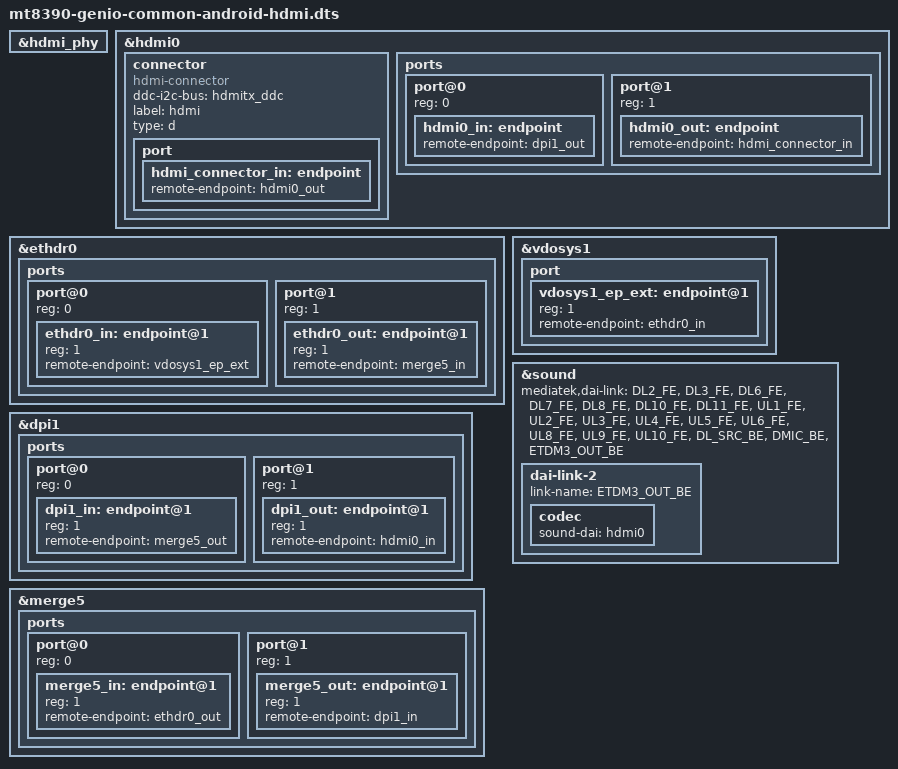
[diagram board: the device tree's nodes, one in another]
// SPDX-License-Identifier: GPL-2.0
/*
 * Copyright (c) 2025 BayLibre, SAS.
 * Author: Vitor Sato Eschholz <vsatoes@baylibre.com>
 */

/dts-v1/;
/plugin/;

#include <dt-bindings/gpio/gpio.h>
#include <dt-bindings/pinctrl/mediatek,mt8188-pinfunc.h>

#include "mt8390-genio-common-android.dtsi"

&hdmi_phy {
	status = "okay";
};

&hdmi0 {
	status = "okay";

	connector {
		compatible = "hdmi-connector";
		ddc-i2c-bus = <&hdmitx_ddc>;
		label = "hdmi";
		type = "d";

		port {
			hdmi_connector_in: endpoint {
				remote-endpoint = <&hdmi0_out>;
			};
		};
	};

	ports {
		#address-cells = <1>;
		#size-cells = <0>;

		port@0 {
			reg = <0>;

			hdmi0_in: endpoint {
				remote-endpoint = <&dpi1_out>;
			};
		};

		port@1 {
			reg = <1>;

			hdmi0_out: endpoint {
				remote-endpoint = <&hdmi_connector_in>;
			};
		};
	};
};

&ethdr0 {
	ports {
		#address-cells = <1>;
		#size-cells = <0>;

		port@0 {
			#address-cells = <1>;
			#size-cells = <0>;
			reg = <0>;

			ethdr0_in: endpoint@1 {
				reg = <1>;
				remote-endpoint = <&vdosys1_ep_ext>;
			};
		};

		port@1 {
			#address-cells = <1>;
			#size-cells = <0>;
			reg = <1>;

			ethdr0_out: endpoint@1 {
				reg = <1>;
				remote-endpoint = <&merge5_in>;
			};
		};
	};
};

&dpi1 {
	status = "okay";

	ports {
		#address-cells = <1>;
		#size-cells = <0>;

		port@0 {
			#address-cells = <1>;
			#size-cells = <0>;
			reg = <0>;

			dpi1_in: endpoint@1 {
				reg = <1>;
				remote-endpoint = <&merge5_out>;
			};
		};

		port@1 {
			#address-cells = <1>;
			#size-cells = <0>;
			reg = <1>;

			dpi1_out: endpoint@1 {
				reg = <1>;
				remote-endpoint = <&hdmi0_in>;
			};
		};
	};
};

&merge5 {
	ports {
		#address-cells = <1>;
		#size-cells = <0>;

		port@0 {
			#address-cells = <1>;
			#size-cells = <0>;
			reg = <0>;

			merge5_in: endpoint@1 {
				reg = <1>;
				remote-endpoint = <&ethdr0_out>;
			};
		};

		port@1 {
			#address-cells = <1>;
			#size-cells = <0>;
			reg = <1>;

			merge5_out: endpoint@1 {
				reg = <1>;
				remote-endpoint = <&dpi1_in>;
			};
		};
	};
};

&vdosys1 {
	port {
		#address-cells = <1>;
		#size-cells = <0>;

		vdosys1_ep_ext: endpoint@1 {
			reg = <1>;
			remote-endpoint = <&ethdr0_in>;
		};
	};
};

&sound {
	mediatek,dai-link =
		"DL2_FE", "DL3_FE", "DL6_FE", "DL7_FE", "DL8_FE", "DL10_FE", "DL11_FE",
		"UL1_FE", "UL2_FE", "UL3_FE", "UL4_FE", "UL5_FE", "UL6_FE", "UL8_FE",
		"UL9_FE", "UL10_FE", "DL_SRC_BE", "DMIC_BE", "ETDM3_OUT_BE";

	dai-link-2 {
		link-name = "ETDM3_OUT_BE";

		codec {
			sound-dai = <&hdmi0>;
		};
	};
};
